# STM32F0x1 register map
File version: 1.2
CPU: CM0 r0p0, little endian, no MPU, no FPU, 2 interrupt priority bits
Registers are 32-bit, read-write, reset 0x0 unless marked. A register's access mark holds for its fields unless they carry their own. Offsets are from the block's base; [hi:lo] are bit positions; 'fields as' and 'values as' point back to an identical list.

## CRS — Clock recovery system
Base 0x40006C00
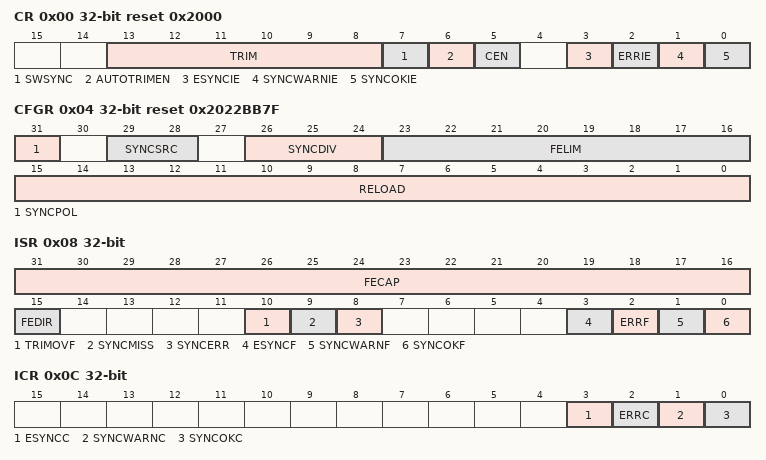
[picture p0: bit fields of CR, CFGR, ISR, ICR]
0x00 CR reset 0x2000 — control register
  [13:8] TRIM — HSI48 oscillator smooth trimming
  [7] SWSYNC — Generate software SYNC event
    1=Sync (A software sync is generated)
  [6] AUTOTRIMEN — Automatic trimming enable
    0=Disabled (Automatic trimming disabled); 1=Enabled (Automatic trimming enabled)
  [5] CEN — Frequency error counter enable
    0=Disabled (Frequency error counter disabled); 1=Enabled (Frequency error counter enabled)
  [3] ESYNCIE — Expected SYNC interrupt enable
    0=Disabled (Interrupt disabled); 1=Enabled (Interrupt enabled)
  [2] ERRIE — Synchronization or trimming error interrupt enable
    values as ESYNCIE
  [1] SYNCWARNIE — SYNC warning interrupt enable
    values as ESYNCIE
  [0] SYNCOKIE — SYNC event OK interrupt enable
    values as ESYNCIE
0x04 CFGR reset 0x2022BB7F — configuration register
  [31] SYNCPOL — SYNC polarity selection
    0=RisingEdge (SYNC active on rising edge); 1=FallingEdge (SYNC active on falling edge)
  [29:28] SYNCSRC — SYNC signal source selection
    0=GPIO_AF (GPIO AF (crs_sync_in_1) selected as SYNC signal source); 1=LSE (LSE (crs_sync_in_2) selected as SYNC signal source); 2=USB_SOF (USB SOF (crs_sync_in_3) selected as SYNC signal source)
  [26:24] SYNCDIV — SYNC divider
    0=Div1 (SYNC not divided); 1=Div2 (SYNC divided by 2); 2=Div4 (SYNC divided by 4); 3=Div8 (SYNC divided by 8); 4=Div16 (SYNC divided by 16); 5=Div32 (SYNC divided by 32); 6=Div64 (SYNC divided by 64); 7=Div128 (SYNC divided by 128)
  [23:16] FELIM — Frequency error limit
  [15:0] RELOAD — Counter reload value
0x08 ISR ro — interrupt and status register
  [31:16] FECAP — Frequency error capture
  [15] FEDIR — Frequency error direction
    0=UpCounting (Error in up-counting direction); 1=DownCounting (Error in down-counting direction)
  [10] TRIMOVF — Trimming overflow or underflow
    0=NotSignaled (Signal not set); 1=Signaled (Signal set)
  [9] SYNCMISS — SYNC missed
    0=NotSignaled (Signal not set); 1=Signaled (Signal set)
  [8] SYNCERR — SYNC error
    0=NotSignaled (Signal not set); 1=Signaled (Signal set)
  [3] ESYNCF — Expected SYNC flag
    0=NotSignaled (Signal not set); 1=Signaled (Signal set)
  [2] ERRF — Error flag
    0=NotSignaled (Signal not set); 1=Signaled (Signal set)
  [1] SYNCWARNF — SYNC warning flag
    0=NotSignaled (Signal not set); 1=Signaled (Signal set)
  [0] SYNCOKF — SYNC event OK flag
    0=NotSignaled (Signal not set); 1=Signaled (Signal set)
0x0C ICR — interrupt flag clear register
  [all] fields
    1=Clear flag
  [3] ESYNCC — Expected SYNC clear flag
  [2] ERRC — Error clear flag
  [1] SYNCWARNC — SYNC warning clear flag
  [0] SYNCOKC — SYNC event OK clear flag

## SCB — System control block
Base 0xE000ED00
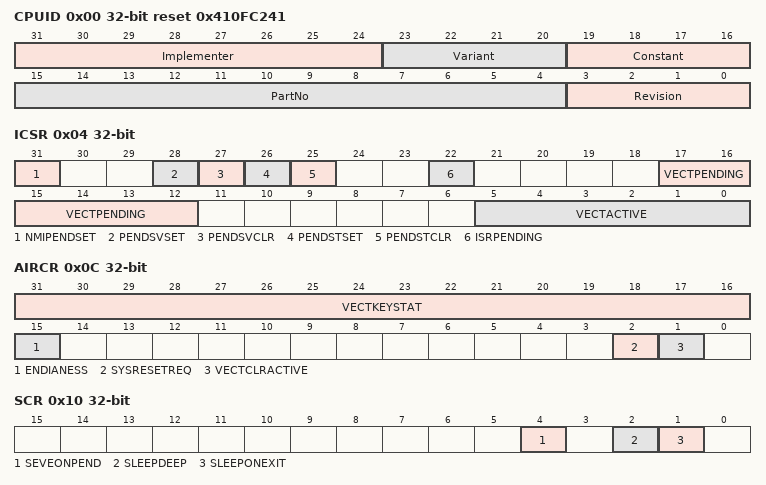
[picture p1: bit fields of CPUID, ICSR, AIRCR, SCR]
0x00 CPUID ro reset 0x410FC241 — CPUID base register
  [31:24] Implementer — Implementer code
  [23:20] Variant — Variant number
  [19:16] Constant — Reads as 0xF
  [15:4] PartNo — Part number of the processor
  [3:0] Revision — Revision number
0x04 ICSR — Interrupt control and state register
  [31] NMIPENDSET — NMI set-pending bit.
  [28] PENDSVSET — PendSV set-pending bit
  [27] PENDSVCLR — PendSV clear-pending bit
  [26] PENDSTSET — SysTick exception set-pending bit
  [25] PENDSTCLR — SysTick exception clear-pending bit
  [22] ISRPENDING — Interrupt pending flag
  [17:12] VECTPENDING — Pending vector
  [5:0] VECTACTIVE — Active vector
0x0C AIRCR — Application interrupt and reset control register
  [31:16] VECTKEYSTAT — Register key
  [15] ENDIANESS
  [2] SYSRESETREQ
  [1] VECTCLRACTIVE
0x10 SCR — System control register
  [4] SEVEONPEND — Send Event on Pending bit
  [2] SLEEPDEEP
  [1] SLEEPONEXIT
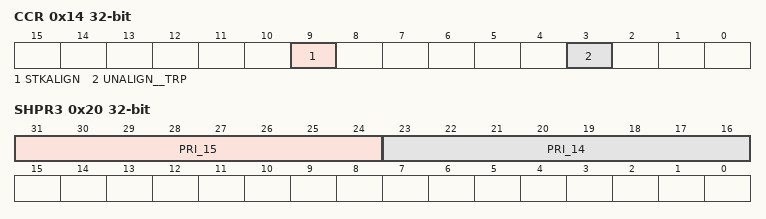
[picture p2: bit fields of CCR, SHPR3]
0x14 CCR — Configuration and control register
  [9] STKALIGN, [3] UNALIGN__TRP
0x1C SHPR2 — System handler priority registers
  [31:24] PRI_11 — Priority of system handler 11
0x20 SHPR3 — System handler priority registers
  [31:24] PRI_15 — Priority of system handler 15
  [23:16] PRI_14 — Priority of system handler 14

## STK — SysTick timer
Base 0xE000E010
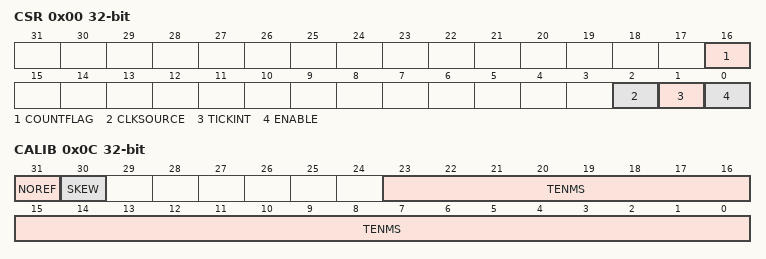
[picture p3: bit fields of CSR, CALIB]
0x00 CSR — SysTick control and status register
  [16] COUNTFLAG
  [2] CLKSOURCE — Clock source selection
  [1] TICKINT — SysTick exception request enable
  [0] ENABLE — Counter enable
0x04 RVR — SysTick reload value register
  [23:0] RELOAD — RELOAD value
0x08 CVR — SysTick current value register
  [23:0] CURRENT — Current counter value
0x0C CALIB — SysTick calibration value register
  [31] NOREF — NOREF flag. Reads as zero
  [30] SKEW — SKEW flag: Indicates whether the TENMS value is exact
  [23:0] TENMS — Calibration value
